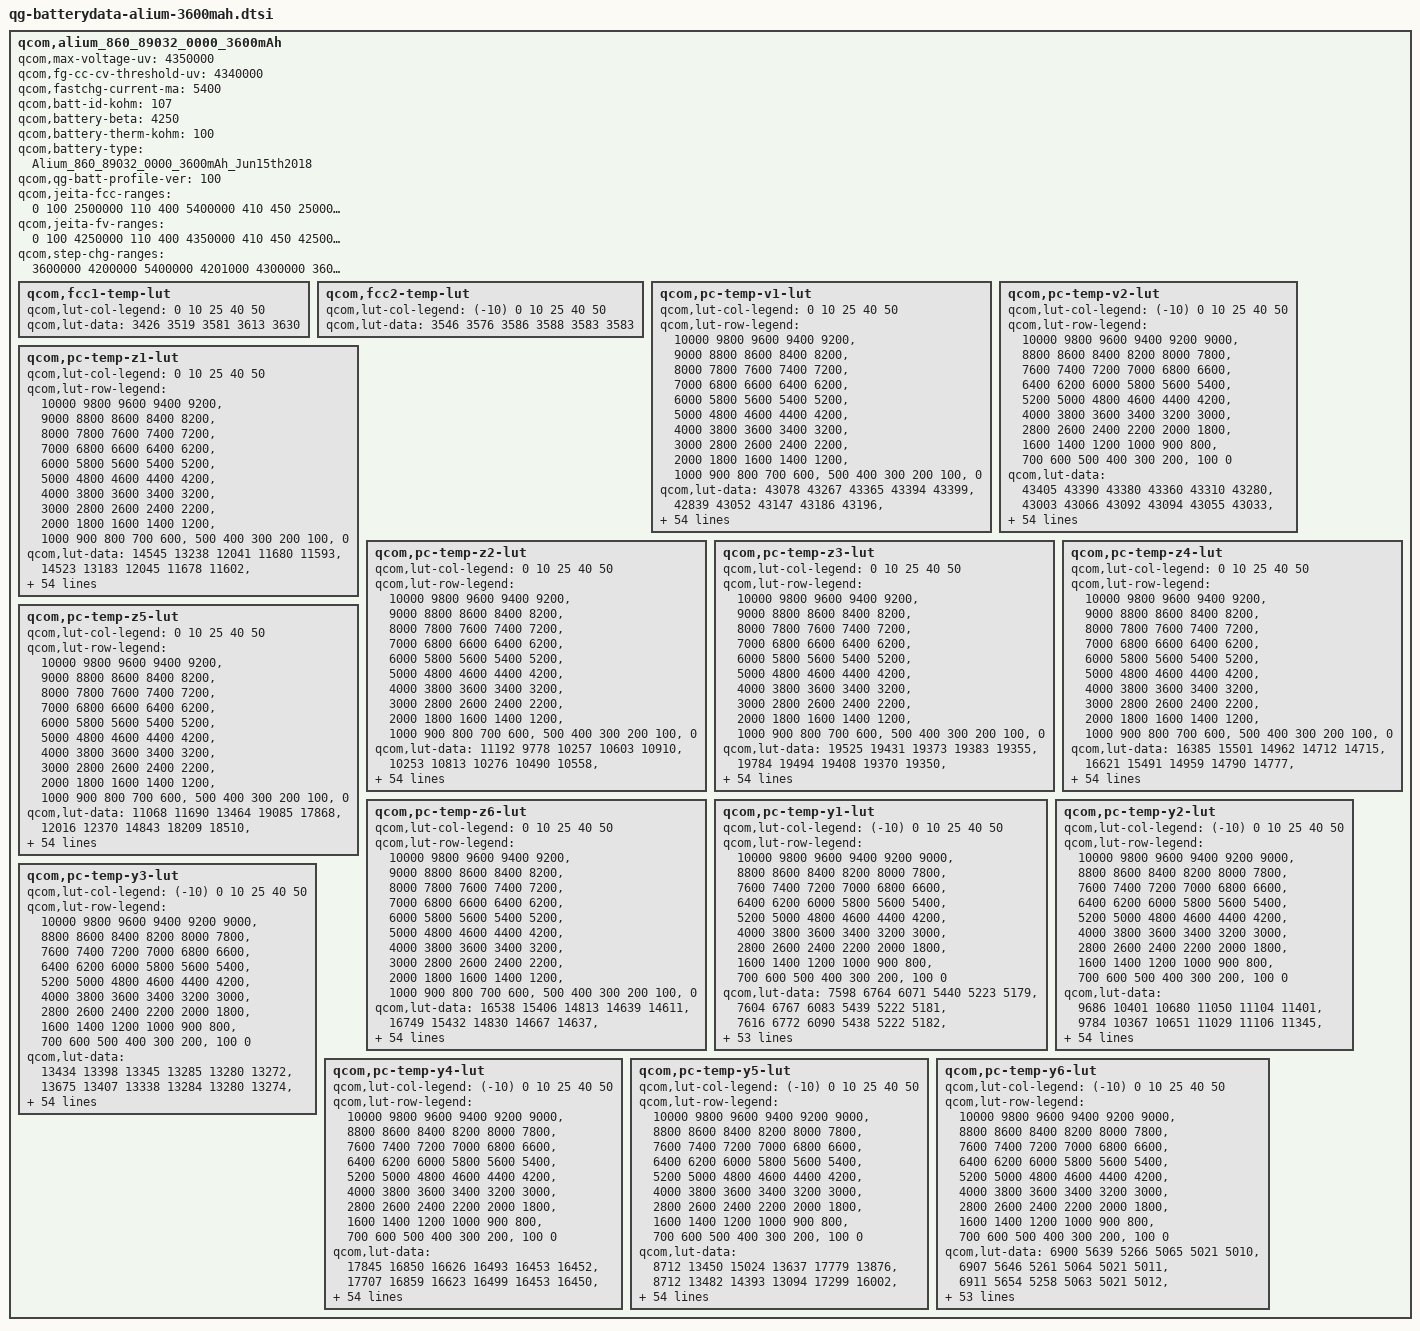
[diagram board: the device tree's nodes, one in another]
/*
 * Copyright (c) 2018, The Linux Foundation. All rights reserved.
 *
 * This program is free software; you can redistribute it and/or modify
 * it under the terms of the GNU General Public License version 2 and
 * only version 2 as published by the Free Software Foundation.
 *
 * This program is distributed in the hope that it will be useful,
 * but WITHOUT ANY WARRANTY; without even the implied warranty of
 * MERCHANTABILITY or FITNESS FOR A PARTICULAR PURPOSE.  See the
 * GNU General Public License for more details.
 */

qcom,alium_860_89032_0000_3600mAh {
	/* Alium_860_89032_0000_3600mAh_averaged_MasterSlave_Jun15th2018 */
	qcom,max-voltage-uv = <4350000>;
	qcom,fg-cc-cv-threshold-uv = <4340000>;
	qcom,fastchg-current-ma = <5400>;
	qcom,batt-id-kohm = <107>;
	qcom,battery-beta = <4250>;
	qcom,battery-therm-kohm = <100>;
	qcom,battery-type = "Alium_860_89032_0000_3600mAh_Jun15th2018";
	qcom,qg-batt-profile-ver = <100>;

	qcom,jeita-fcc-ranges = <0  100  2500000
				110 400  5400000
				410 450  2500000>;
	qcom,jeita-fv-ranges = <0   100  4250000
				110 400  4350000
				410 450  4250000>;
	qcom,step-chg-ranges = <3600000  4200000  5400000
				4201000  4300000  3600000
				4301000  4350000  2500000>;

	qcom,fcc1-temp-lut {
		qcom,lut-col-legend = <0 10 25 40 50>;
		qcom,lut-data = <3426 3519 3581 3613 3630>;
	};

	qcom,fcc2-temp-lut {
		qcom,lut-col-legend = <(-10) 0 10 25 40 50>;
		qcom,lut-data = <3546 3576 3586 3588 3583 3583>;
	};

	qcom,pc-temp-v1-lut {
		qcom,lut-col-legend = <0 10 25 40 50>;
		qcom,lut-row-legend = <10000 9800 9600 9400 9200>,
			<9000 8800 8600 8400 8200>,
			<8000 7800 7600 7400 7200>,
			<7000 6800 6600 6400 6200>,
			<6000 5800 5600 5400 5200>,
			<5000 4800 4600 4400 4200>,
			<4000 3800 3600 3400 3200>,
			<3000 2800 2600 2400 2200>,
			<2000 1800 1600 1400 1200>,
			<1000 900 800 700 600>,
			<500 400 300 200 100>,
			<0>;
		qcom,lut-data = <43078 43267 43365 43394 43399>,
			<42839 43052 43147 43186 43196>,
			<42609 42823 42920 42964 42981>,
			<42392 42591 42693 42738 42759>,
			<42186 42370 42469 42513 42535>,
			<41983 42159 42248 42289 42310>,
			<41776 41953 42032 42066 42085>,
			<41565 41745 41820 41847 41863>,
			<41376 41534 41607 41630 41645>,
			<41226 41338 41393 41412 41426>,
			<41086 41189 41206 41205 41212>,
			<40873 41057 41063 41032 41014>,
			<40523 40858 40918 40878 40833>,
			<40155 40509 40680 40678 40639>,
			<39917 40145 40325 40390 40407>,
			<39757 39925 40039 40116 40180>,
			<39638 39781 39894 39960 40010>,
			<39541 39669 39779 39850 39877>,
			<39455 39579 39646 39699 39715>,
			<39364 39489 39487 39469 39489>,
			<39266 39366 39306 39235 39257>,
			<39165 39210 39096 39058 39072>,
			<39060 39042 38900 38912 38919>,
			<38955 38854 38767 38784 38785>,
			<38859 38675 38671 38668 38668>,
			<38773 38551 38581 38562 38562>,
			<38692 38462 38490 38466 38462>,
			<38619 38394 38403 38377 38369>,
			<38552 38343 38327 38296 38283>,
			<38491 38301 38257 38222 38203>,
			<38439 38261 38195 38156 38132>,
			<38392 38224 38142 38097 38067>,
			<38348 38190 38095 38043 38010>,
			<38306 38161 38052 37989 37952>,
			<38265 38135 38015 37938 37895>,
			<38223 38102 37976 37886 37836>,
			<38181 38066 37935 37830 37771>,
			<38128 38020 37890 37771 37701>,
			<38054 37950 37823 37699 37623>,
			<37964 37850 37727 37613 37538>,
			<37862 37740 37617 37512 37439>,
			<37739 37617 37494 37390 37318>,
			<37601 37487 37361 37256 37185>,
			<37448 37354 37221 37119 37052>,
			<37327 37238 37120 37019 36955>,
			<37241 37161 37057 36960 36898>,
			<37209 37134 37035 36943 36881>,
			<37182 37113 37018 36927 36865>,
			<37146 37086 36991 36896 36829>,
			<37036 36976 36855 36724 36634>,
			<36712 36636 36510 36372 36278>,
			<36253 36181 36056 35916 35819>,
			<35673 35600 35476 35330 35231>,
			<34889 34811 34685 34533 34429>,
			<33644 33573 33450 33289 33175>,
			<30000 30000 30000 30000 30000>;
	};

	qcom,pc-temp-v2-lut {
		qcom,lut-col-legend = <(-10) 0 10 25 40 50>;
		qcom,lut-row-legend = <10000 9800 9600 9400 9200 9000>,
			<8800 8600 8400 8200 8000 7800>,
			<7600 7400 7200 7000 6800 6600>,
			<6400 6200 6000 5800 5600 5400>,
			<5200 5000 4800 4600 4400 4200>,
			<4000 3800 3600 3400 3200 3000>,
			<2800 2600 2400 2200 2000 1800>,
			<1600 1400 1200 1000 900 800>,
			<700 600 500 400 300 200>,
			<100 0>;
		qcom,lut-data = <43405 43390 43380 43360 43310 43280>,
			<43003 43066 43092 43094 43055 43033>,
			<42659 42770 42823 42839 42808 42792>,
			<42388 42505 42573 42597 42570 42556>,
			<42183 42269 42342 42369 42341 42328>,
			<41972 42046 42121 42146 42116 42104>,
			<41647 41828 41907 41928 41893 41879>,
			<41314 41618 41700 41715 41674 41657>,
			<41242 41409 41488 41499 41455 41438>,
			<41295 41194 41265 41273 41232 41219>,
			<41338 41020 41073 41079 41031 41013>,
			<41030 40918 40949 40949 40883 40839>,
			<40301 40831 40837 40833 40747 40674>,
			<39816 40619 40617 40621 40542 40474>,
			<39553 40056 40158 40222 40214 40226>,
			<39352 39574 39750 39893 39934 39999>,
			<39187 39400 39544 39757 39792 39836>,
			<39047 39287 39391 39659 39684 39694>,
			<38903 39154 39240 39507 39524 39512>,
			<38748 38998 39093 39269 39281 39271>,
			<38600 38840 38951 39039 39045 39043>,
			<38473 38688 38809 38867 38872 38870>,
			<38360 38541 38673 38723 38728 38725>,
			<38269 38408 38551 38598 38603 38600>,
			<38195 38289 38441 38488 38492 38488>,
			<38132 38186 38339 38387 38390 38385>,
			<38076 38102 38245 38293 38296 38290>,
			<38026 38033 38158 38206 38208 38200>,
			<37976 37977 38077 38128 38127 38118>,
			<37929 37931 38001 38058 38053 38043>,
			<37882 37891 37932 37991 37985 37974>,
			<37835 37852 37869 37926 37922 37912>,
			<37786 37815 37814 37863 37863 37853>,
			<37734 37776 37764 37798 37793 37778>,
			<37680 37735 37722 37732 37704 37675>,
			<37621 37692 37680 37666 37610 37565>,
			<37558 37641 37633 37602 37526 37469>,
			<37492 37582 37583 37538 37448 37384>,
			<37421 37513 37524 37470 37374 37308>,
			<37348 37429 37450 37396 37302 37235>,
			<37274 37332 37362 37312 37222 37156>,
			<37201 37229 37261 37208 37121 37056>,
			<37130 37124 37145 37082 36997 36933>,
			<37054 37029 37028 36964 36881 36820>,
			<36966 36949 36952 36902 36830 36771>,
			<36849 36873 36903 36875 36801 36743>,
			<36768 36823 36880 36854 36784 36726>,
			<36666 36763 36850 36823 36756 36699>,
			<36509 36668 36775 36740 36671 36604>,
			<36284 36467 36557 36486 36422 36338>,
			<35954 36107 36161 36071 36005 35919>,
			<35477 35597 35626 35539 35482 35397>,
			<34808 34917 34941 34844 34796 34717>,
			<33818 33942 34003 33928 33918 33830>,
			<32458 32548 32795 32808 32663 32496>,
			<28619 28270 28017 28020 27984 27930>;
	};

	qcom,pc-temp-z1-lut {
		qcom,lut-col-legend = <0 10 25 40 50>;
		qcom,lut-row-legend = <10000 9800 9600 9400 9200>,
			<9000 8800 8600 8400 8200>,
			<8000 7800 7600 7400 7200>,
			<7000 6800 6600 6400 6200>,
			<6000 5800 5600 5400 5200>,
			<5000 4800 4600 4400 4200>,
			<4000 3800 3600 3400 3200>,
			<3000 2800 2600 2400 2200>,
			<2000 1800 1600 1400 1200>,
			<1000 900 800 700 600>,
			<500 400 300 200 100>,
			<0>;
		qcom,lut-data = <14545 13238 12041 11680 11593>,
			<14523 13183 12045 11678 11602>,
			<14531 13174 12043 11685 11612>,
			<14535 13182 12039 11687 11616>,
			<14547 13186 12035 11688 11618>,
			<14571 13181 12033 11688 11620>,
			<14591 13164 12034 11689 11623>,
			<14582 13150 12035 11692 11626>,
			<14551 13149 12037 11694 11629>,
			<14518 13154 12041 11697 11631>,
			<14486 13152 12045 11701 11634>,
			<14452 13134 12047 11704 11639>,
			<14403 13116 12047 11707 11643>,
			<14352 13102 12043 11707 11644>,
			<14318 13096 12036 11705 11644>,
			<14291 13097 12033 11703 11644>,
			<14262 13097 12036 11707 11647>,
			<14226 13100 12042 11714 11653>,
			<14194 13111 12052 11721 11659>,
			<14181 13129 12065 11726 11663>,
			<14179 13150 12076 11731 11667>,
			<14186 13172 12085 11736 11672>,
			<14195 13188 12093 11741 11676>,
			<14207 13195 12101 11745 11681>,
			<14215 13201 12109 11751 11686>,
			<14220 13210 12116 11756 11690>,
			<14223 13222 12123 11760 11695>,
			<14228 13229 12130 11764 11699>,
			<14239 13234 12137 11768 11703>,
			<14255 13242 12143 11772 11707>,
			<14279 13250 12149 11776 11711>,
			<14302 13257 12154 11780 11716>,
			<14310 13265 12160 11784 11720>,
			<14314 13278 12166 11789 11725>,
			<14320 13297 12174 11794 11729>,
			<14343 13315 12181 11799 11733>,
			<14395 13333 12189 11802 11736>,
			<14443 13346 12197 11804 11738>,
			<14481 13351 12202 11807 11740>,
			<14512 13353 12205 11809 11741>,
			<14514 13357 12209 11811 11742>,
			<14472 13369 12217 11813 11744>,
			<14451 13384 12223 11815 11745>,
			<14446 13399 12224 11816 11746>,
			<14433 13385 12228 11817 11746>,
			<14447 13396 12231 11819 11746>,
			<14441 13396 12232 11819 11745>,
			<14440 13403 12233 11819 11746>,
			<14431 13399 12239 11820 11747>,
			<14460 13394 12241 11824 11750>,
			<14470 13423 12251 11830 11755>,
			<14506 13430 12275 11839 11760>,
			<14485 13470 12295 11850 11770>,
			<14544 13512 12338 11868 11782>,
			<14544 13512 12338 11868 11782>,
			<14544 13512 12338 11868 11782>;
	};

	qcom,pc-temp-z2-lut {
		qcom,lut-col-legend = <0 10 25 40 50>;
		qcom,lut-row-legend = <10000 9800 9600 9400 9200>,
			<9000 8800 8600 8400 8200>,
			<8000 7800 7600 7400 7200>,
			<7000 6800 6600 6400 6200>,
			<6000 5800 5600 5400 5200>,
			<5000 4800 4600 4400 4200>,
			<4000 3800 3600 3400 3200>,
			<3000 2800 2600 2400 2200>,
			<2000 1800 1600 1400 1200>,
			<1000 900 800 700 600>,
			<500 400 300 200 100>,
			<0>;
		qcom,lut-data = <11192 9778 10257 10603 10910>,
			<10253 10813 10276 10490 10558>,
			<9726 10534 10287 10428 10436>,
			<9734 10061 10282 10413 10412>,
			<9760 9938 10269 10392 10406>,
			<9775 9923 10261 10380 10404>,
			<9777 9909 10257 10375 10408>,
			<9772 9898 10258 10370 10412>,
			<9765 9890 10262 10368 10412>,
			<9755 9884 10265 10372 10421>,
			<9746 9880 10259 10375 10444>,
			<9750 9878 10227 10382 10452>,
			<9766 9881 10199 10414 10451>,
			<9772 9895 10216 10429 10452>,
			<9752 9907 10260 10399 10450>,
			<9717 9910 10282 10371 10439>,
			<9701 9914 10279 10383 10449>,
			<9697 9923 10269 10418 10506>,
			<9693 9949 10295 10465 10551>,
			<9686 9981 10388 10545 10559>,
			<9673 10014 10446 10602 10559>,
			<9662 10050 10419 10553 10531>,
			<9655 10080 10371 10429 10478>,
			<9649 10101 10339 10379 10444>,
			<9631 10116 10316 10398 10420>,
			<9588 10124 10303 10422 10405>,
			<9554 10131 10300 10409 10406>,
			<9540 10135 10301 10384 10415>,
			<9483 10134 10309 10376 10426>,
			<9426 10131 10329 10376 10445>,
			<9408 10130 10351 10380 10472>,
			<9395 10131 10373 10399 10506>,
			<9386 10133 10396 10437 10548>,
			<9378 10137 10420 10474 10594>,
			<9372 10146 10446 10506 10651>,
			<9368 10154 10463 10533 10695>,
			<9374 10162 10468 10556 10712>,
			<9380 10167 10471 10580 10722>,
			<9389 10171 10479 10593 10733>,
			<9398 10176 10491 10596 10745>,
			<9397 10178 10497 10597 10753>,
			<9384 10169 10490 10609 10755>,
			<9380 10140 10483 10625 10759>,
			<9386 9964 10481 10631 10781>,
			<9324 9926 10454 10642 10811>,
			<9305 9932 10438 10669 10808>,
			<9287 9948 10463 10697 10858>,
			<9289 9933 10557 10698 10889>,
			<9274 9965 10622 10758 10917>,
			<9278 9923 10533 10711 10837>,
			<9316 9884 10462 10634 10693>,
			<9326 9807 10425 10609 10671>,
			<9285 9724 10395 10535 10591>,
			<9245 9615 10285 10458 10500>,
			<9245 9615 10285 10458 10500>,
			<9245 9615 10285 10458 10500>;
	};

	qcom,pc-temp-z3-lut {
		qcom,lut-col-legend = <0 10 25 40 50>;
		qcom,lut-row-legend = <10000 9800 9600 9400 9200>,
			<9000 8800 8600 8400 8200>,
			<8000 7800 7600 7400 7200>,
			<7000 6800 6600 6400 6200>,
			<6000 5800 5600 5400 5200>,
			<5000 4800 4600 4400 4200>,
			<4000 3800 3600 3400 3200>,
			<3000 2800 2600 2400 2200>,
			<2000 1800 1600 1400 1200>,
			<1000 900 800 700 600>,
			<500 400 300 200 100>,
			<0>;
		qcom,lut-data = <19525 19431 19373 19383 19355>,
			<19784 19494 19408 19370 19350>,
			<19920 19574 19438 19372 19351>,
			<19937 19651 19450 19380 19356>,
			<19918 19673 19455 19382 19359>,
			<19895 19676 19456 19383 19362>,
			<19884 19677 19454 19381 19362>,
			<19879 19677 19451 19376 19359>,
			<19877 19680 19448 19372 19355>,
			<19874 19682 19446 19372 19353>,
			<19872 19668 19440 19372 19352>,
			<19877 19628 19423 19367 19352>,
			<19894 19610 19400 19355 19349>,
			<19909 19638 19406 19350 19345>,
			<19892 19671 19439 19363 19347>,
			<19843 19665 19457 19379 19351>,
			<19796 19628 19436 19373 19348>,
			<19760 19594 19408 19356 19338>,
			<19726 19567 19407 19352 19335>,
			<19697 19550 19425 19366 19342>,
			<19672 19554 19438 19379 19351>,
			<19654 19573 19439 19379 19357>,
			<19644 19591 19439 19374 19361>,
			<19636 19603 19437 19373 19362>,
			<19628 19612 19434 19380 19360>,
			<19619 19613 19433 19386 19358>,
			<19607 19611 19439 19383 19356>,
			<19596 19607 19445 19378 19354>,
			<19583 19601 19446 19374 19352>,
			<19567 19594 19444 19369 19350>,
			<19549 19588 19442 19365 19348>,
			<19530 19583 19439 19362 19345>,
			<19514 19578 19434 19360 19342>,
			<19499 19571 19431 19359 19338>,
			<19486 19563 19429 19358 19334>,
			<19479 19557 19426 19358 19332>,
			<19483 19551 19422 19358 19332>,
			<19491 19546 19418 19357 19334>,
			<19513 19542 19415 19356 19334>,
			<19535 19539 19414 19351 19331>,
			<19526 19535 19412 19347 19329>,
			<19496 19530 19410 19347 19330>,
			<19483 19519 19408 19347 19330>,
			<19481 19451 19404 19347 19331>,
			<19372 19379 19382 19344 19327>,
			<19345 19348 19360 19337 19320>,
			<19337 19340 19358 19328 19312>,
			<19339 19335 19342 19326 19312>,
			<19316 19318 19331 19324 19309>,
			<19320 19317 19352 19335 19324>,
			<19371 19345 19355 19339 19331>,
			<19418 19350 19357 19342 19332>,
			<19442 19348 19353 19346 19335>,
			<19464 19360 19359 19349 19340>,
			<19464 19360 19359 19349 19340>,
			<19464 19360 19359 19349 19340>;
	};

	qcom,pc-temp-z4-lut {
		qcom,lut-col-legend = <0 10 25 40 50>;
		qcom,lut-row-legend = <10000 9800 9600 9400 9200>,
			<9000 8800 8600 8400 8200>,
			<8000 7800 7600 7400 7200>,
			<7000 6800 6600 6400 6200>,
			<6000 5800 5600 5400 5200>,
			<5000 4800 4600 4400 4200>,
			<4000 3800 3600 3400 3200>,
			<3000 2800 2600 2400 2200>,
			<2000 1800 1600 1400 1200>,
			<1000 900 800 700 600>,
			<500 400 300 200 100>,
			<0>;
		qcom,lut-data = <16385 15501 14962 14712 14715>,
			<16621 15491 14959 14790 14777>,
			<16602 15456 14922 14802 14786>,
			<16518 15370 14881 14784 14773>,
			<16384 15265 14843 14759 14750>,
			<16241 15178 14812 14736 14726>,
			<16119 15106 14786 14721 14710>,
			<16009 15051 14764 14710 14700>,
			<15894 15008 14752 14704 14694>,
			<15746 14969 14746 14701 14689>,
			<15604 14928 14744 14698 14685>,
			<15557 14895 14744 14693 14681>,
			<15579 14889 14745 14687 14673>,
			<15600 14901 14749 14689 14670>,
			<15554 14908 14754 14704 14683>,
			<15436 14889 14752 14715 14696>,
			<15339 14846 14732 14699 14686>,
			<15282 14813 14713 14669 14663>,
			<15245 14793 14712 14671 14662>,
			<15230 14781 14722 14728 14708>,
			<15221 14780 14742 14778 14758>,
			<15217 14783 14794 14782 14763>,
			<15221 14793 14846 14777 14751>,
			<15227 14842 14846 14766 14737>,
			<15232 14904 14815 14739 14722>,
			<15237 14918 14783 14717 14709>,
			<15244 14915 14759 14707 14700>,
			<15250 14910 14740 14702 14693>,
			<15262 14895 14729 14697 14687>,
			<15275 14872 14722 14693 14682>,
			<15283 14853 14717 14690 14677>,
			<15290 14837 14715 14686 14673>,
			<15294 14821 14714 14682 14670>,
			<15292 14806 14713 14682 14669>,
			<15285 14792 14713 14684 14672>,
			<15265 14778 14712 14686 14677>,
			<15218 14764 14710 14689 14683>,
			<15171 14753 14707 14691 14689>,
			<15100 14750 14704 14691 14691>,
			<15036 14748 14701 14691 14688>,
			<15028 14745 14698 14690 14685>,
			<15035 14740 14695 14688 14684>,
			<15033 14741 14690 14685 14683>,
			<15011 14800 14682 14681 14680>,
			<15037 14827 14679 14667 14668>,
			<15046 14838 14675 14645 14644>,
			<15051 14840 14669 14641 14637>,
			<15043 14842 14681 14633 14624>,
			<15056 14851 14689 14629 14622>,
			<15040 14847 14670 14638 14636>,
			<15003 14839 14678 14645 14640>,
			<14990 14846 14681 14646 14645>,
			<14996 14862 14691 14647 14646>,
			<15017 14877 14695 14650 14646>,
			<15017 14877 14695 14650 14646>,
			<15017 14877 14695 14650 14646>;
	};

	qcom,pc-temp-z5-lut {
		qcom,lut-col-legend = <0 10 25 40 50>;
		qcom,lut-row-legend = <10000 9800 9600 9400 9200>,
			<9000 8800 8600 8400 8200>,
			<8000 7800 7600 7400 7200>,
			<7000 6800 6600 6400 6200>,
			<6000 5800 5600 5400 5200>,
			<5000 4800 4600 4400 4200>,
			<4000 3800 3600 3400 3200>,
			<3000 2800 2600 2400 2200>,
			<2000 1800 1600 1400 1200>,
			<1000 900 800 700 600>,
			<500 400 300 200 100>,
			<0>;
		qcom,lut-data = <11068 11690 13464 19085 17868>,
			<12016 12370 14843 18209 18510>,
			<12567 13373 16287 18434 19041>,
			<12767 14431 17166 19331 19871>,
			<12906 14953 17644 19970 20772>,
			<13043 15275 18035 20553 21985>,
			<13254 15589 18448 20812 22838>,
			<13520 16021 18878 20763 23075>,
			<13787 16665 19253 20832 23069>,
			<14074 17170 19532 21287 23403>,
			<14425 17078 19373 21540 24108>,
			<14893 16220 17894 20839 24888>,
			<15428 16083 16100 18925 24832>,
			<15715 18342 16976 18223 24189>,
			<15770 20589 20553 20659 24472>,
			<15797 20502 22513 23616 25498>,
			<15834 19565 21295 23828 25788>,
			<15830 19061 19385 22969 25708>,
			<15750 18918 21990 23440 25684>,
			<15580 18870 30436 27428 25707>,
			<15309 20532 34653 30469 25746>,
			<15057 25755 30884 27232 24220>,
			<14852 31080 25218 20500 20766>,
			<14649 35866 22212 18547 19399>,
			<14406 39481 20440 20518 19854>,
			<14102 39590 19963 22400 20596>,
			<13801 37343 21441 23200 21434>,
			<13549 34779 23939 23840 22513>,
			<13290 32437 26091 24203 23750>,
			<13021 30286 28345 24605 25226>,
			<12746 29196 30150 25017 26620>,
			<12479 28629 31211 25585 27804>,
			<12282 28181 32038 26640 28805>,
			<12126 27688 32872 28101 29029>,
			<11990 27267 33745 30291 28636>,
			<11896 27207 34089 31579 28289>,
			<11945 27442 32771 31455 28513>,
			<12049 27808 30864 31087 28942>,
			<12350 28315 30537 30322 28828>,
			<12671 28953 30633 27821 27284>,
			<12642 29117 30687 26060 26101>,
			<12299 27717 30577 26308 26287>,
			<12208 24781 30313 26635 26505>,
			<12309 16408 28848 26643 26112>,
			<11428 13096 22891 26468 25271>,
			<11198 12322 18301 26248 25109>,
			<11112 12144 18213 22490 22887>,
			<11116 12041 15832 22757 25790>,
			<10935 11705 14733 23506 25696>,
			<10976 11757 17791 27597 30144>,
			<11440 12275 17295 25361 28944>,
			<11648 12197 17311 24873 26253>,
			<11657 11966 16067 25059 25290>,
			<11600 11884 16052 23410 24581>,
			<11600 11884 16052 23410 24581>,
			<11600 11884 16052 23410 24581>;
	};

	qcom,pc-temp-z6-lut {
		qcom,lut-col-legend = <0 10 25 40 50>;
		qcom,lut-row-legend = <10000 9800 9600 9400 9200>,
			<9000 8800 8600 8400 8200>,
			<8000 7800 7600 7400 7200>,
			<7000 6800 6600 6400 6200>,
			<6000 5800 5600 5400 5200>,
			<5000 4800 4600 4400 4200>,
			<4000 3800 3600 3400 3200>,
			<3000 2800 2600 2400 2200>,
			<2000 1800 1600 1400 1200>,
			<1000 900 800 700 600>,
			<500 400 300 200 100>,
			<0>;
		qcom,lut-data = <16538 15406 14813 14639 14611>,
			<16749 15432 14830 14667 14637>,
			<16795 15447 14830 14674 14643>,
			<16769 15440 14820 14671 14641>,
			<16699 15411 14805 14663 14634>,
			<16612 15372 14791 14653 14625>,
			<16540 15333 14779 14645 14619>,
			<16482 15307 14768 14638 14613>,
			<16423 15289 14762 14634 14608>,
			<16352 15271 14759 14633 14606>,
			<16282 15242 14755 14632 14604>,
			<16243 15204 14746 14628 14603>,
			<16229 15190 14734 14620 14598>,
			<16213 15202 14738 14617 14595>,
			<16158 15216 14756 14631 14602>,
			<16064 15204 14764 14643 14610>,
			<15984 15167 14745 14634 14604>,
			<15930 15138 14722 14613 14590>,
			<15887 15120 14722 14612 14588>,
			<15858 15110 14737 14646 14613>,
			<15836 15113 14757 14675 14640>,
			<15826 15129 14785 14678 14644>,
			<15826 15150 14807 14675 14644>,
			<15831 15182 14806 14671 14642>,
			<15836 15213 14793 14664 14635>,
			<15841 15221 14782 14658 14628>,
			<15846 15221 14776 14653 14623>,
			<15850 15220 14772 14648 14620>,
			<15854 15214 14769 14645 14617>,
			<15856 15204 14766 14641 14614>,
			<15856 15196 14763 14638 14611>,
			<15856 15188 14761 14635 14608>,
			<15855 15180 14760 14632 14605>,
			<15853 15174 14759 14632 14604>,
			<15851 15168 14759 14633 14604>,
			<15851 15164 14758 14634 14604>,
			<15853 15160 14756 14636 14607>,
			<15855 15157 14754 14637 14611>,
			<15855 15157 14752 14637 14612>,
			<15854 15158 14751 14634 14610>,
			<15851 15158 14750 14632 14608>,
			<15842 15157 14749 14631 14608>,
			<15832 15156 14747 14631 14607>,
			<15821 15148 14743 14630 14607>,
			<15777 15126 14731 14621 14600>,
			<15764 15120 14719 14609 14585>,
			<15763 15114 14716 14602 14578>,
			<15759 15116 14713 14598 14572>,
			<15757 15111 14711 14595 14570>,
			<15765 15116 14716 14605 14584>,
			<15777 15136 14723 14612 14591>,
			<15805 15152 14732 14616 14594>,
			<15840 15173 14739 14621 14598>,
			<15893 15213 14754 14628 14605>,
			<15893 15213 14754 14628 14605>,
			<15893 15213 14754 14628 14605>;
	};

	qcom,pc-temp-y1-lut {
		qcom,lut-col-legend = <(-10) 0 10 25 40 50>;
		qcom,lut-row-legend = <10000 9800 9600 9400 9200 9000>,
			<8800 8600 8400 8200 8000 7800>,
			<7600 7400 7200 7000 6800 6600>,
			<6400 6200 6000 5800 5600 5400>,
			<5200 5000 4800 4600 4400 4200>,
			<4000 3800 3600 3400 3200 3000>,
			<2800 2600 2400 2200 2000 1800>,
			<1600 1400 1200 1000 900 800>,
			<700 600 500 400 300 200>,
			<100 0>;
		qcom,lut-data = <7598 6764 6071 5440 5223 5179>,
			<7604 6767 6083 5439 5222 5181>,
			<7616 6772 6090 5438 5222 5182>,
			<7629 6778 6094 5436 5222 5184>,
			<7640 6782 6096 5435 5223 5185>,
			<7645 6784 6096 5434 5223 5187>,
			<7644 6784 6092 5434 5224 5187>,
			<7642 6784 6086 5434 5226 5188>,
			<7635 6781 6085 5435 5228 5189>,
			<7612 6774 6088 5436 5229 5190>,
			<7594 6768 6090 5437 5231 5192>,
			<7603 6766 6086 5437 5232 5193>,
			<7624 6767 6080 5437 5234 5195>,
			<7644 6772 6081 5438 5236 5197>,
			<7668 6789 6096 5445 5241 5202>,
			<7683 6807 6107 5453 5244 5204>,
			<7674 6820 6111 5455 5244 5205>,
			<7655 6831 6115 5458 5245 5205>,
			<7640 6832 6116 5460 5246 5206>,
			<7626 6817 6114 5461 5248 5209>,
			<7619 6805 6114 5464 5251 5212>,
			<7638 6807 6125 5468 5255 5216>,
			<7673 6815 6139 5472 5259 5219>,
			<7681 6821 6141 5477 5262 5223>,
			<7680 6824 6136 5481 5265 5226>,
			<7684 6828 6135 5485 5267 5230>,
			<7689 6840 6144 5489 5270 5234>,
			<7692 6860 6155 5494 5274 5237>,
			<7690 6871 6158 5499 5277 5240>,
			<7672 6876 6162 5505 5280 5242>,
			<7648 6878 6167 5510 5283 5245>,
			<7641 6875 6171 5515 5287 5248>,
			<7643 6871 6175 5520 5290 5252>,
			<7645 6871 6176 5523 5293 5255>,
			<7649 6869 6177 5526 5296 5257>,
			<7656 6867 6179 5529 5298 5259>,
			<7671 6879 6183 5531 5300 5260>,
			<7690 6895 6188 5533 5301 5261>,
			<7693 6895 6193 5534 5301 5262>,
			<7679 6883 6197 5535 5302 5262>,
			<7669 6879 6202 5537 5303 5263>,
			<7670 6885 6209 5541 5305 5265>,
			<7670 6891 6220 5544 5306 5266>,
			<7670 6898 6217 5546 5307 5267>,
			<7674 6904 6224 5551 5310 5269>,
			<7684 6923 6224 5553 5310 5270>,
			<7689 6920 6233 5556 5310 5270>,
			<7718 6926 6243 5556 5310 5270>,
			<7735 6923 6251 5558 5311 5270>,
			<7724 6942 6247 5561 5314 5272>,
			<7721 6975 6265 5570 5317 5275>,
			<7736 7003 6293 5585 5324 5280>,
			<7777 7007 6312 5604 5331 5286>,
			<7862 7038 6346 5623 5340 5292>,
			<7862 7038 6346 5623 5340 5292>,
			<7862 7038 6346 5623 5340 5292>;
	};

	qcom,pc-temp-y2-lut {
		qcom,lut-col-legend = <(-10) 0 10 25 40 50>;
		qcom,lut-row-legend = <10000 9800 9600 9400 9200 9000>,
			<8800 8600 8400 8200 8000 7800>,
			<7600 7400 7200 7000 6800 6600>,
			<6400 6200 6000 5800 5600 5400>,
			<5200 5000 4800 4600 4400 4200>,
			<4000 3800 3600 3400 3200 3000>,
			<2800 2600 2400 2200 2000 1800>,
			<1600 1400 1200 1000 900 800>,
			<700 600 500 400 300 200>,
			<100 0>;
		qcom,lut-data = <9686 10401 10680 11050 11104 11401>,
			<9784 10367 10651 11029 11106 11345>,
			<9844 10346 10618 11003 11105 11260>,
			<9875 10335 10585 10974 11102 11170>,
			<9887 10331 10557 10941 11096 11098>,
			<9890 10330 10539 10906 11089 11068>,
			<9836 10343 10530 10861 11080 11075>,
			<9739 10365 10523 10815 11067 11086>,
			<9714 10360 10518 10793 11048 11085>,
			<9726 10302 10514 10780 11017 11066>,
			<9749 10260 10512 10771 10981 11044>,
			<9880 10338 10522 10756 10934 11003>,
			<10116 10474 10547 10736 10885 10947>,
			<10170 10505 10586 10738 10874 10940>,
			<9944 10486 10664 10781 10896 10992>,
			<9729 10473 10720 10835 10928 11033>,
			<9701 10495 10746 10897 10988 11035>,
			<9694 10532 10766 10960 11059 11032>,
			<9688 10541 10781 10991 11079 11043>,
			<9682 10540 10795 11004 11080 11097>,
			<9677 10537 10806 11018 11082 11163>,
			<9674 10483 10815 11049 11128 11225>,
			<9672 10313 10824 11092 11200 11283>,
			<9670 10193 10827 11124 11234 11325>,
			<9667 10079 10832 11151 11254 11356>,
			<9664 10012 10836 11169 11271 11377>,
			<9663 9998 10834 11180 11289 11395>,
			<9662 9984 10826 11184 11309 11414>,
			<9661 9965 10822 11175 11317 11445>,
			<9660 9940 10820 11150 11329 11500>,
			<9659 9913 10815 11136 11341 11537>,
			<9659 9889 10729 11139 11328 11522>,
			<9658 9867 10574 11151 11311 11482>,
			<9657 9842 10507 11164 11315 11466>,
			<9656 9813 10490 11161 11321 11473>,
			<9656 9786 10478 11140 11317 11478>,
			<9655 9762 10470 11112 11316 11484>,
			<9655 9732 10507 11097 11321 11496>,
			<9654 9708 10556 11103 11323 11495>,
			<9654 9694 10525 11104 11318 11473>,
			<9654 9684 10426 11103 11314 11461>,
			<9654 9675 10396 11106 11316 11468>,
			<9654 9668 10406 11101 11314 11471>,
			<9653 9662 10267 11078 11283 11464>,
			<9653 9659 10199 11060 11283 11440>,
			<9653 9659 10180 11025 11296 11394>,
			<9653 9658 10256 11021 11274 11345>,
			<9653 9657 10321 11043 11240 11336>,
			<9653 9656 10323 11048 11247 11344>,
			<9652 9656 10295 10982 11294 11322>,
			<9652 9654 10240 10956 11255 11261>,
			<9652 9653 10172 10913 11134 11175>,
			<9652 9652 10118 10825 11023 11061>,
			<9650 9652 10099 10780 10831 10826>,
			<9650 9652 10099 10780 10831 10826>,
			<9650 9652 10099 10780 10831 10826>;
	};

	qcom,pc-temp-y3-lut {
		qcom,lut-col-legend = <(-10) 0 10 25 40 50>;
		qcom,lut-row-legend = <10000 9800 9600 9400 9200 9000>,
			<8800 8600 8400 8200 8000 7800>,
			<7600 7400 7200 7000 6800 6600>,
			<6400 6200 6000 5800 5600 5400>,
			<5200 5000 4800 4600 4400 4200>,
			<4000 3800 3600 3400 3200 3000>,
			<2800 2600 2400 2200 2000 1800>,
			<1600 1400 1200 1000 900 800>,
			<700 600 500 400 300 200>,
			<100 0>;
		qcom,lut-data = <13434 13398 13345 13285 13280 13272>,
			<13675 13407 13338 13284 13280 13274>,
			<13823 13420 13334 13283 13280 13275>,
			<13901 13433 13334 13283 13280 13277>,
			<13931 13444 13336 13283 13280 13278>,
			<13936 13449 13340 13285 13280 13278>,
			<13804 13449 13347 13288 13280 13278>,
			<13564 13448 13355 13293 13281 13278>,
			<13499 13451 13358 13295 13281 13278>,
			<13498 13470 13359 13296 13281 13277>,
			<13499 13484 13360 13296 13281 13277>,
			<13523 13470 13373 13303 13284 13279>,
			<13572 13441 13392 13313 13289 13282>,
			<13584 13425 13393 13314 13290 13283>,
			<13548 13416 13371 13310 13288 13282>,
			<13516 13410 13351 13307 13286 13282>,
			<13520 13407 13346 13309 13288 13282>,
			<13536 13405 13343 13313 13292 13283>,
			<13543 13402 13339 13313 13292 13283>,
			<13545 13397 13334 13305 13287 13280>,
			<13546 13391 13329 13296 13283 13277>,
			<13548 13381 13324 13288 13281 13276>,
			<13552 13365 13319 13283 13280 13275>,
			<13557 13351 13318 13282 13279 13275>,
			<13568 13340 13317 13283 13278 13275>,
			<13586 13335 13317 13284 13278 13274>,
			<13605 13336 13317 13283 13278 13274>,
			<13625 13339 13317 13283 13277 13274>,
			<13647 13343 13317 13285 13277 13274>,
			<13675 13347 13317 13289 13277 13273>,
			<13709 13352 13317 13292 13277 13273>,
			<13746 13357 13312 13293 13278 13273>,
			<13786 13364 13305 13292 13278 13274>,
			<13834 13372 13302 13292 13279 13274>,
			<13889 13385 13303 13290 13278 13274>,
			<13952 13400 13304 13288 13278 13273>,
			<14017 13416 13307 13286 13278 13273>,
			<14082 13434 13314 13284 13277 13273>,
			<14146 13456 13320 13283 13277 13273>,
			<14209 13488 13324 13283 13277 13273>,
			<14273 13532 13327 13283 13277 13273>,
			<14339 13585 13333 13283 13278 13274>,
			<14405 13648 13342 13283 13278 13274>,
			<14482 13731 13345 13284 13278 13274>,
			<14570 13843 13353 13283 13278 13274>,
			<14605 13890 13360 13291 13279 13276>,
			<14655 13886 13365 13292 13281 13277>,
			<14684 13912 13378 13296 13283 13280>,
			<14733 14009 13393 13298 13282 13280>,
			<14859 14104 13394 13294 13281 13277>,
			<14999 14246 13402 13296 13280 13277>,
			<15153 14472 13423 13301 13283 13281>,
			<15376 14712 13458 13305 13286 13284>,
			<16172 14971 13514 13315 13290 13286>,
			<16172 14971 13514 13315 13290 13286>,
			<16172 14971 13514 13315 13290 13286>;
	};

	qcom,pc-temp-y4-lut {
		qcom,lut-col-legend = <(-10) 0 10 25 40 50>;
		qcom,lut-row-legend = <10000 9800 9600 9400 9200 9000>,
			<8800 8600 8400 8200 8000 7800>,
			<7600 7400 7200 7000 6800 6600>,
			<6400 6200 6000 5800 5600 5400>,
			<5200 5000 4800 4600 4400 4200>,
			<4000 3800 3600 3400 3200 3000>,
			<2800 2600 2400 2200 2000 1800>,
			<1600 1400 1200 1000 900 800>,
			<700 600 500 400 300 200>,
			<100 0>;
		qcom,lut-data = <17845 16850 16626 16493 16453 16452>,
			<17707 16859 16623 16499 16453 16450>,
			<17643 16875 16623 16504 16455 16449>,
			<17641 16896 16626 16507 16456 16448>,
			<17685 16923 16631 16509 16458 16448>,
			<17761 16953 16638 16510 16459 16448>,
			<17959 16995 16646 16508 16461 16449>,
			<18315 17038 16657 16506 16462 16452>,
			<18708 17060 16668 16506 16465 16454>,
			<19236 17069 16679 16513 16469 16457>,
			<19572 17084 16696 16524 16475 16461>,
			<19006 17415 16799 16542 16489 16473>,
			<17760 17958 16951 16564 16509 16488>,
			<17274 17986 16977 16573 16513 16492>,
			<17223 17320 16899 16575 16509 16491>,
			<17197 16817 16810 16579 16507 16490>,
			<17184 16821 16750 16620 16529 16506>,
			<17165 16866 16699 16681 16570 16536>,
			<17135 16877 16663 16682 16576 16541>,
			<17076 16837 16634 16593 16532 16509>,
			<17012 16792 16611 16517 16486 16475>,
			<16969 16768 16596 16504 16468 16461>,
			<16936 16750 16584 16498 16457 16451>,
			<16927 16747 16578 16495 16456 16450>,
			<16931 16735 16574 16491 16456 16450>,
			<16939 16719 16571 16489 16457 16451>,
			<16945 16707 16570 16491 16459 16453>,
			<16955 16695 16570 16493 16462 16456>,
			<16966 16694 16569 16494 16465 16460>,
			<16978 16706 16564 16496 16471 16465>,
			<16990 16724 16560 16498 16478 16472>,
			<17002 16743 16564 16500 16488 16483>,
			<17014 16767 16573 16502 16499 16496>,
			<17027 16792 16580 16500 16501 16498>,
			<17040 16818 16585 16489 16484 16481>,
			<17052 16845 16589 16478 16463 16460>,
			<17064 16879 16594 16475 16452 16451>,
			<17077 16927 16600 16473 16446 16447>,
			<17095 16964 16604 16474 16446 16448>,
			<17121 16978 16617 16477 16450 16453>,
			<17160 16988 16637 16480 16455 16458>,
			<17211 16994 16652 16483 16456 16459>,
			<17278 17008 16664 16484 16454 16456>,
			<17363 17031 16681 16481 16445 16443>,
			<17450 17090 16711 16491 16449 16446>,
			<17435 17135 16736 16501 16471 16474>,
			<17438 17159 16742 16516 16496 16504>,
			<17389 17194 16787 16546 16537 16546>,
			<17360 17262 16870 16574 16540 16536>,
			<17381 17283 16862 16542 16494 16484>,
			<17398 17284 16856 16542 16480 16473>,
			<17425 17312 16891 16573 16496 16487>,
			<17507 17393 16998 16635 16528 16517>,
			<18186 17570 17197 16862 16705 16664>,
			<18186 17570 17197 16862 16705 16664>,
			<18186 17570 17197 16862 16705 16664>;
	};

	qcom,pc-temp-y5-lut {
		qcom,lut-col-legend = <(-10) 0 10 25 40 50>;
		qcom,lut-row-legend = <10000 9800 9600 9400 9200 9000>,
			<8800 8600 8400 8200 8000 7800>,
			<7600 7400 7200 7000 6800 6600>,
			<6400 6200 6000 5800 5600 5400>,
			<5200 5000 4800 4600 4400 4200>,
			<4000 3800 3600 3400 3200 3000>,
			<2800 2600 2400 2200 2000 1800>,
			<1600 1400 1200 1000 900 800>,
			<700 600 500 400 300 200>,
			<100 0>;
		qcom,lut-data = <8712 13450 15024 13637 17779 13876>,
			<8712 13482 14393 13094 17299 16002>,
			<9887 13538 13920 12763 16795 17370>,
			<12171 13602 13593 12592 16319 18144>,
			<13352 13655 13402 12528 15924 18488>,
			<13712 13682 13338 12519 15663 18564>,
			<12526 13686 13491 13011 15524 18119>,
			<10345 13688 13732 13797 15423 17285>,
			<9855 13494 13762 13896 15233 16665>,
			<10836 12338 13637 13520 14742 16018>,
			<12278 11512 13460 13263 14463 15589>,
			<14305 12246 13117 13605 14692 15613>,
			<16658 13838 12700 14184 15051 15805>,
			<17024 14948 12908 14300 15117 15807>,
			<14139 15828 14686 14149 14970 15538>,
			<11513 16242 16074 14033 14913 15280>,
			<11523 16069 16259 14411 15080 15197>,
			<11996 15810 16323 15261 15416 15147>,
			<12172 15770 16274 15815 15959 15251>,
			<12062 15859 16079 16180 16933 16031>,
			<11868 15956 15846 16328 17499 16947>,
			<11620 15469 15368 15383 17703 17632>,
			<11312 13975 14705 13688 17924 18203>,
			<11115 12872 14496 13266 17959 18431>,
			<11014 12058 14552 13626 17682 18509>,
			<10964 11631 14629 13920 17362 18511>,
			<10973 11596 14709 13944 17173 18320>,
			<10988 11605 14796 13932 17044 17852>,
			<10995 11588 14900 14573 17019 17407>,
			<11030 11538 15113 16622 17008 17007>,
			<11086 11527 15270 18010 17024 16810>,
			<11136 11527 14539 18405 17391 17083>,
			<11177 11500 13186 18651 18220 17910>,
			<11216 11497 12702 18616 19096 18783>,
			<11256 11585 12708 17851 20108 19561>,
			<11296 11690 12725 16773 20954 20137>,
			<11333 11737 12833 15892 21243 20622>,
			<11364 11658 13487 15086 21079 21066>,
			<11372 11570 14099 14616 20668 21138>,
			<11354 11602 14046 14527 20112 20711>,
			<11333 11673 13559 14611 19900 20367>,
			<11347 11689 13647 14598 20136 20790>,
			<11447 11633 14091 14488 20830 22215>,
			<11628 11564 13261 14690 21851 23634>,
			<11886 11464 12890 13840 19650 20132>,
			<12228 11536 12810 15945 17300 17267>,
			<12464 11547 13361 15880 17100 16566>,
			<12844 11910 14094 16530 16574 16161>,
			<12886 12441 14613 16353 15911 15963>,
			<12844 12583 14513 15967 17037 16654>,
			<12567 12345 14561 17027 17428 17457>,
			<12151 12056 14328 17704 18241 18950>,
			<11887 11870 14282 17302 18299 19121>,
			<11109 11677 14642 17219 17830 18283>,
			<11109 11677 14642 17219 17830 18283>,
			<11109 11677 14642 17219 17830 18283>;
	};

	qcom,pc-temp-y6-lut {
		qcom,lut-col-legend = <(-10) 0 10 25 40 50>;
		qcom,lut-row-legend = <10000 9800 9600 9400 9200 9000>,
			<8800 8600 8400 8200 8000 7800>,
			<7600 7400 7200 7000 6800 6600>,
			<6400 6200 6000 5800 5600 5400>,
			<5200 5000 4800 4600 4400 4200>,
			<4000 3800 3600 3400 3200 3000>,
			<2800 2600 2400 2200 2000 1800>,
			<1600 1400 1200 1000 900 800>,
			<700 600 500 400 300 200>,
			<100 0>;
		qcom,lut-data = <6900 5639 5266 5065 5021 5010>,
			<6907 5646 5261 5064 5021 5011>,
			<6911 5654 5258 5063 5021 5012>,
			<6911 5662 5258 5064 5021 5013>,
			<6908 5670 5260 5065 5022 5013>,
			<6903 5678 5262 5066 5023 5014>,
			<6855 5686 5268 5068 5023 5015>,
			<6776 5694 5276 5071 5025 5015>,
			<6772 5702 5281 5074 5026 5016>,
			<6911 5708 5283 5076 5027 5017>,
			<7024 5719 5288 5079 5029 5018>,
			<6900 5804 5324 5090 5036 5023>,
			<6611 5932 5379 5103 5045 5030>,
			<6465 5932 5387 5106 5047 5032>,
			<6414 5744 5349 5105 5045 5031>,
			<6390 5602 5310 5104 5043 5031>,
			<6395 5604 5291 5117 5051 5036>,
			<6409 5621 5276 5138 5065 5045>,
			<6413 5625 5263 5138 5067 5047>,
			<6412 5613 5251 5107 5051 5035>,
			<6410 5600 5242 5078 5035 5023>,
			<6413 5590 5235 5069 5028 5018>,
			<6426 5582 5230 5064 5025 5015>,
			<6444 5577 5229 5063 5024 5015>,
			<6469 5575 5230 5063 5024 5015>,
			<6500 5574 5231 5064 5024 5016>,
			<6530 5579 5232 5065 5025 5016>,
			<6560 5589 5235 5066 5026 5017>,
			<6592 5602 5237 5068 5027 5018>,
			<6630 5619 5238 5072 5029 5020>,
			<6673 5639 5239 5076 5031 5022>,
			<6719 5661 5240 5078 5035 5026>,
			<6770 5688 5241 5079 5039 5030>,
			<6823 5717 5243 5078 5040 5031>,
			<6880 5750 5247 5074 5035 5026>,
			<6940 5787 5251 5070 5029 5020>,
			<7001 5830 5256 5068 5026 5018>,
			<7062 5880 5264 5067 5024 5016>,
			<7124 5938 5274 5066 5024 5017>,
			<7187 6002 5285 5067 5025 5018>,
			<7249 6076 5296 5069 5027 5020>,
			<7312 6161 5311 5070 5028 5021>,
			<7379 6261 5328 5071 5027 5020>,
			<7458 6383 5344 5072 5025 5017>,
			<7552 6532 5369 5074 5027 5018>,
			<7589 6585 5388 5083 5033 5027>,
			<7631 6596 5395 5089 5042 5037>,
			<7646 6631 5423 5100 5055 5051>,
			<7684 6743 5466 5110 5056 5048>,
			<7789 6847 5472 5099 5042 5031>,
			<7903 6977 5491 5102 5038 5029>,
			<8038 7181 5547 5117 5046 5036>,
			<8244 7391 5646 5141 5058 5047>,
			<9160 7653 5795 5217 5112 5092>,
			<9160 7653 5795 5217 5112 5092>,
			<9160 7653 5795 5217 5112 5092>;
	};
};
